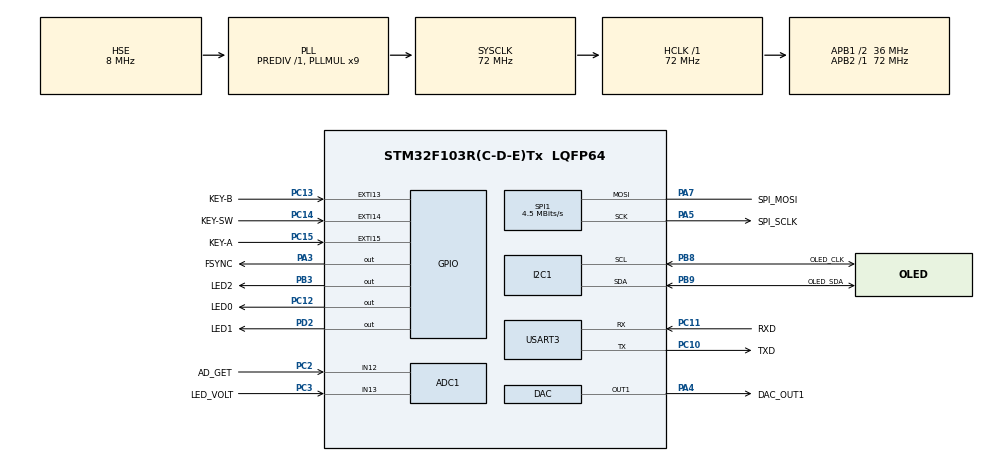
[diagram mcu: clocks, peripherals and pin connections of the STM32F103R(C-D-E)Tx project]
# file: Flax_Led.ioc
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ADC1.Channel-0\#ChannelRegularConversion=ADC_CHANNEL_12
ADC1.NbrOfConversionFlag=1
ADC1.Rank-0\#ChannelRegularConversion=1
ADC1.SamplingTime-0\#ChannelRegularConversion=ADC_SAMPLETIME_1CYCLE_5
ADC1.master=1
Dma.I2C1_TX.0.Direction=DMA_MEMORY_TO_PERIPH
Dma.I2C1_TX.0.Instance=DMA1_Channel6
Dma.I2C1_TX.0.MemDataAlignment=DMA_MDATAALIGN_BYTE
Dma.I2C1_TX.0.MemInc=DMA_MINC_ENABLE
Dma.I2C1_TX.0.Mode=DMA_NORMAL
Dma.I2C1_TX.0.PeriphDataAlignment=DMA_PDATAALIGN_BYTE
Dma.I2C1_TX.0.PeriphInc=DMA_PINC_DISABLE
Dma.I2C1_TX.0.Priority=DMA_PRIORITY_MEDIUM
Dma.Request0=I2C1_TX
FREERTOS.Queues01=KEY_NUM_Queue,16,uint16_t,0,Dynamic,NULL,NULL;OLED_DIS_Queue,32,uint16_t,0,Dynamic,NULL,NULL
FREERTOS.Tasks01=defaultTask,24,128,StartDefaultTask,Default,NULL,Dynamic,NULL,NULL;Oled_Task,8,256,OledTask,Default,NULL,Dynamic,NULL,NULL;Key_Task,8,128,KeyTask,Default,NULL,Dynamic,NULL,NULL
FREERTOS.configTICK_RATE_HZ=100
I2C1.I2C_Mode=I2C_Fast
Mcu.Family=STM32F1
Mcu.Name=STM32F103R(C-D-E)Tx
Mcu.Package=LQFP64
NVIC.DMA1_Channel6_IRQn=true\:5\:0\:false\:false\:true\:true\:false\:true\:true
NVIC.PriorityGroup=NVIC_PRIORITYGROUP_4
NVIC.TIM7_IRQn=true\:15\:0\:false\:false\:true\:false\:false\:true\:true
NVIC.TimeBase=TIM7_IRQn
NVIC.TimeBaseIP=TIM7
PA13.Mode=Serial_Wire
PA13.Signal=SYS_JTMS-SWDIO
PA14.Mode=Serial_Wire
PA14.Signal=SYS_JTCK-SWCLK
PA3.GPIO_Label=FSYNC
PA3.Signal=GPIO_Output
PA4.GPIO_Label=DAC_OUT1
PA4.Signal=COMP_DAC1_group
PA5.GPIO_Label=SPI_SCLK
PA5.Mode=Simplex_Bidirectional_Master
PA5.Signal=SPI1_SCK
PA7.GPIO_Label=SPI_MOSI
PA7.Mode=Simplex_Bidirectional_Master
PA7.Signal=SPI1_MOSI
PB3.GPIO_Label=LED2
PB3.Signal=GPIO_Output
PB8.GPIO_Label=OLED_CLK
PB8.Mode=I2C
PB8.Signal=I2C1_SCL
PB9.GPIO_Label=OLED_SDA
PB9.Mode=I2C
PB9.Signal=I2C1_SDA
PC10.GPIO_Label=TXD
PC10.Mode=Asynchronous
PC10.Signal=USART3_TX
PC11.GPIO_Label=RXD
PC11.Mode=Asynchronous
PC11.Signal=USART3_RX
PC12.GPIO_Label=LED0
PC12.Signal=GPIO_Output
PC13-TAMPER-RTC.GPIO_Label=KEY-B
PC13-TAMPER-RTC.Signal=GPXTI13
PC14-OSC32_IN.GPIO_Label=KEY-SW
PC14-OSC32_IN.Signal=GPXTI14
PC15-OSC32_OUT.GPIO_Label=KEY-A
PC15-OSC32_OUT.Signal=GPXTI15
PC2.GPIO_Label=AD_GET
PC2.Signal=ADCx_IN12
PC3.GPIO_Label=LED_VOLT
PC3.Signal=ADCx_IN13
PD0-OSC_IN.Mode=HSE-External-Oscillator
PD0-OSC_IN.Signal=RCC_OSC_IN
PD1-OSC_OUT.Mode=HSE-External-Oscillator
PD1-OSC_OUT.Signal=RCC_OSC_OUT
PD2.GPIO_Label=LED1
PD2.Signal=GPIO_Output
ProjectManager.HeapSize=0x200
ProjectManager.StackSize=0x400
ProjectManager.TargetToolchain=MDK-ARM V5.27
RCC.ADCPresc=RCC_ADCPCLK2_DIV6
RCC.AHBFreq_Value=72000000
RCC.APB1CLKDivider=RCC_HCLK_DIV2
RCC.APB1Freq_Value=36000000
RCC.APB1TimFreq_Value=72000000
RCC.APB2Freq_Value=72000000
RCC.APB2TimFreq_Value=72000000
RCC.HCLKFreq_Value=72000000
RCC.PLLMUL=RCC_PLL_MUL9
RCC.PLLSourceVirtual=RCC_PLLSOURCE_HSE
RCC.SYSCLKFreq_VALUE=72000000
RCC.SYSCLKSource=RCC_SYSCLKSOURCE_PLLCLK
RCC.USBFreq_Value=72000000
SH.ADCx_IN12.0=ADC1_IN12,IN12
SH.ADCx_IN13.0=ADC1_IN13,IN13
SH.COMP_DAC1_group.0=DAC_OUT1,DAC_OUT1
SPI1.BaudRatePrescaler=SPI_BAUDRATEPRESCALER_16
SPI1.CalculateBaudRate=4.5 MBits/s
SPI1.Direction=SPI_DIRECTION_1LINE
SPI1.Mode=SPI_MODE_MASTER
SPI1.VirtualType=VM_MASTER
USART3.VirtualMode=VM_ASYNC
VP_FREERTOS_VS_CMSIS_V2.Mode=CMSIS_V2
VP_SYS_VS_tim7.Mode=TIM7
board=custom

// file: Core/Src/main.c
/* USER CODE BEGIN Header */
/**
  ******************************************************************************
  * @file           : main.c
  * @brief          : Main program body
  ******************************************************************************
  * @attention
  *
  * Copyright (c) 2024 STMicroelectronics.
  * All rights reserved.
  *
  * This software is licensed under terms that can be found in the LICENSE file
  * in the root directory of this software component.
  * If no LICENSE file comes with this software, it is provided AS-IS.
  *
  ******************************************************************************
  */
/* USER CODE END Header */
#include "main.h"
#include "cmsis_os.h"
#include "adc.h"
#include "dac.h"
#include "dma.h"
#include "i2c.h"
#include "spi.h"
#include "usart.h"
#include "gpio.h"

void SystemClock_Config(void);
void MX_FREERTOS_Init(void);

int main(void)
{

  /* MCU Configuration--------------------------------------------------------*/

  /* Reset of all peripherals, Initializes the Flash interface and the Systick. */
  HAL_Init();

  /* Configure the system clock */
  SystemClock_Config();

  /* Initialize all configured peripherals */
  MX_GPIO_Init();
  MX_DMA_Init();
  MX_ADC1_Init();
  MX_DAC_Init();
  MX_I2C1_Init();
  MX_SPI1_Init();
  MX_USART3_UART_Init();

  /* Init scheduler */
  osKernelInitialize();

  /* Call init function for freertos objects (in cmsis_os2.c) */
  MX_FREERTOS_Init();

  /* Start scheduler */
  osKernelStart();

  /* We should never get here as control is now taken by the scheduler */

  /* Infinite loop */
  while (1)
  {

  }
}

void SystemClock_Config(void)
{
  RCC_OscInitTypeDef RCC_OscInitStruct = {0};
  RCC_ClkInitTypeDef RCC_ClkInitStruct = {0};
  RCC_PeriphCLKInitTypeDef PeriphClkInit = {0};

  /** Initializes the RCC Oscillators according to the specified parameters
  * in the RCC_OscInitTypeDef structure.
  */
  RCC_OscInitStruct.OscillatorType = RCC_OSCILLATORTYPE_HSE;
  RCC_OscInitStruct.HSEState = RCC_HSE_ON;
  RCC_OscInitStruct.HSEPredivValue = RCC_HSE_PREDIV_DIV1;
  RCC_OscInitStruct.HSIState = RCC_HSI_ON;
  RCC_OscInitStruct.PLL.PLLState = RCC_PLL_ON;
  RCC_OscInitStruct.PLL.PLLSource = RCC_PLLSOURCE_HSE;
  RCC_OscInitStruct.PLL.PLLMUL = RCC_PLL_MUL9;
  if (HAL_RCC_OscConfig(&RCC_OscInitStruct) != HAL_OK)
  {
    Error_Handler();
  }

  /** Initializes the CPU, AHB and APB buses clocks
  */
  RCC_ClkInitStruct.ClockType = RCC_CLOCKTYPE_HCLK|RCC_CLOCKTYPE_SYSCLK
                              |RCC_CLOCKTYPE_PCLK1|RCC_CLOCKTYPE_PCLK2;
  RCC_ClkInitStruct.SYSCLKSource = RCC_SYSCLKSOURCE_PLLCLK;
  RCC_ClkInitStruct.AHBCLKDivider = RCC_SYSCLK_DIV1;
  RCC_ClkInitStruct.APB1CLKDivider = RCC_HCLK_DIV2;
  RCC_ClkInitStruct.APB2CLKDivider = RCC_HCLK_DIV1;

  if (HAL_RCC_ClockConfig(&RCC_ClkInitStruct, FLASH_LATENCY_2) != HAL_OK)
  {
    Error_Handler();
  }
  PeriphClkInit.PeriphClockSelection = RCC_PERIPHCLK_ADC;
  PeriphClkInit.AdcClockSelection = RCC_ADCPCLK2_DIV6;
  if (HAL_RCCEx_PeriphCLKConfig(&PeriphClkInit) != HAL_OK)
  {
    Error_Handler();
  }
}

void HAL_TIM_PeriodElapsedCallback(TIM_HandleTypeDef *htim)
{
  if (htim->Instance == TIM7) {
    HAL_IncTick();
  }
}

void Error_Handler(void)
{
  __disable_irq();
  while (1)
  {
  }
}

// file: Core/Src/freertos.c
/* USER CODE BEGIN Header */
/**
  ******************************************************************************
  * File Name          : freertos.c
  * Description        : Code for freertos applications
  ******************************************************************************
  * @attention
  *
  * Copyright (c) 2024 STMicroelectronics.
  * All rights reserved.
  *
  * This software is licensed under terms that can be found in the LICENSE file
  * in the root directory of this software component.
  * If no LICENSE file comes with this software, it is provided AS-IS.
  *
  ******************************************************************************
  */
/* USER CODE END Header */

#include "FreeRTOS.h"
#include "task.h"
#include "main.h"
#include "cmsis_os.h"

/* USER CODE BEGIN Includes */
#include "oled.h"
#include "key.h"
/* USER CODE END Includes */

/* Definitions for defaultTask */
osThreadId_t defaultTaskHandle;
const osThreadAttr_t defaultTask_attributes = {
  .name = "defaultTask",
  .stack_size = 128 * 4,
  .priority = (osPriority_t) osPriorityNormal,
};
/* Definitions for Oled_Task */
osThreadId_t Oled_TaskHandle;
const osThreadAttr_t Oled_Task_attributes = {
  .name = "Oled_Task",
  .stack_size = 256 * 4,
  .priority = (osPriority_t) osPriorityLow,
};
/* Definitions for Key_Task */
osThreadId_t Key_TaskHandle;
const osThreadAttr_t Key_Task_attributes = {
  .name = "Key_Task",
  .stack_size = 128 * 4,
  .priority = (osPriority_t) osPriorityLow,
};
/* Definitions for KEY_NUM_Queue */
osMessageQueueId_t KEY_NUM_QueueHandle;
const osMessageQueueAttr_t KEY_NUM_Queue_attributes = {
  .name = "KEY_NUM_Queue"
};
/* Definitions for OLED_DIS_Queue */
osMessageQueueId_t OLED_DIS_QueueHandle;
const osMessageQueueAttr_t OLED_DIS_Queue_attributes = {
  .name = "OLED_DIS_Queue"
};

void StartDefaultTask(void *argument);
void OledTask(void *argument);
void KeyTask(void *argument);

void MX_FREERTOS_Init(void); /* (MISRA C 2004 rule 8.1) */

void MX_FREERTOS_Init(void) {

  /* Create the queue(s) */
  /* creation of KEY_NUM_Queue */
  KEY_NUM_QueueHandle = osMessageQueueNew (16, sizeof(uint16_t), &KEY_NUM_Queue_attributes);

  /* creation of OLED_DIS_Queue */
  OLED_DIS_QueueHandle = osMessageQueueNew (32, sizeof(uint16_t), &OLED_DIS_Queue_attributes);

  /* Create the thread(s) */
  /* creation of defaultTask */
  defaultTaskHandle = osThreadNew(StartDefaultTask, NULL, &defaultTask_attributes);

  /* creation of Oled_Task */
  Oled_TaskHandle = osThreadNew(OledTask, NULL, &Oled_Task_attributes);

  /* creation of Key_Task */
  Key_TaskHandle = osThreadNew(KeyTask, NULL, &Key_Task_attributes);

}

void StartDefaultTask(void *argument)
{
  for(;;)
  {
    osDelay(1);
  }
}

void OledTask(void *argument)
{
  /* USER CODE BEGIN OledTask */
	OLED_init();
  /* Infinite loop */
  for(;;)
  {
		OLED_Dis();
    osDelay(1);
  }
  /* USER CODE END OledTask */
}

void KeyTask(void *argument)
{
  for(;;)
  {
    osDelay(1);
  }
}
